AUTOSAR XML (schema 4-0-3)
package /ComponentTypes
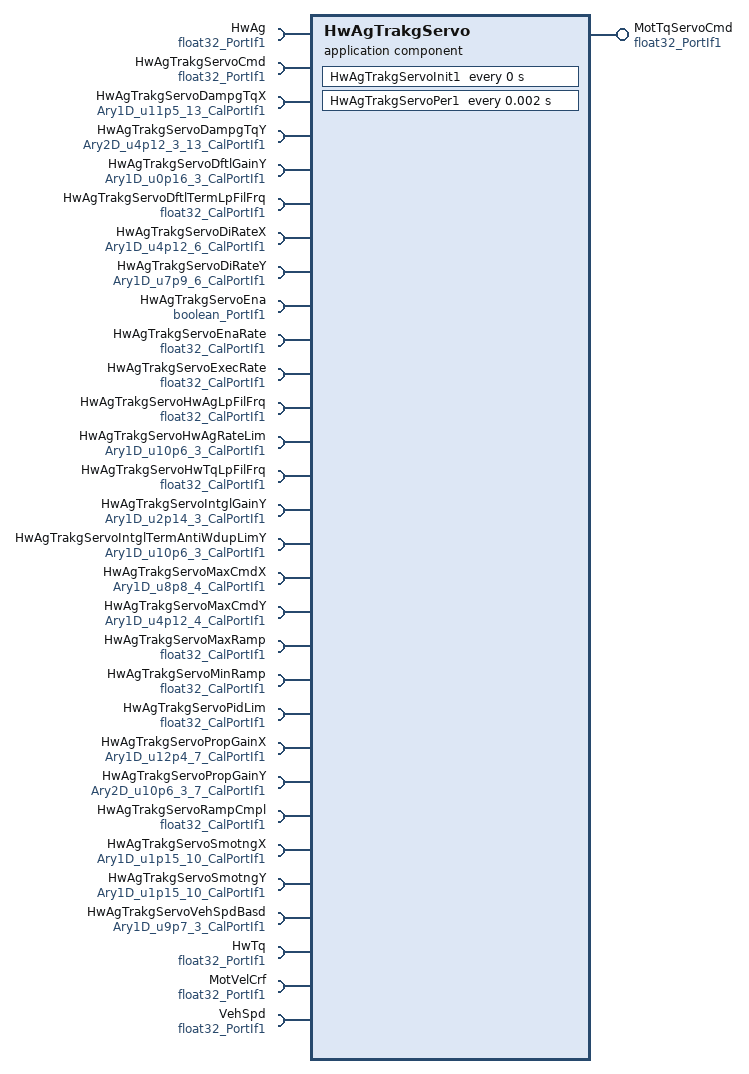
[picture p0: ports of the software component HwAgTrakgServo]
  application sw component type HwAgTrakgServo
    provide port MotTqServoCmd: nonqueued-sender-com-spec{data-element=Val, init-value=0.0}, provided-interface=float32_PortIf1
    30 x require port:
      HwAg: nonqueued-receiver-com-spec{data-element=Val, filter=data-filter-type=ALWAYS, init-value=0.0}, required-interface=float32_PortIf1
      HwAgTrakgServoCmd: nonqueued-receiver-com-spec{data-element=Val, filter=data-filter-type=ALWAYS, init-value=0.0}, required-interface=float32_PortIf1
      HwAgTrakgServoDampgTqX: parameter-require-com-spec{init-value=[0, 3200, 6400, 10724, 11260, 12064, 12868, 13940, 14744, 16620, 21448, 24128, 26808], parameter=Ary1D}, required-interface=Ary1D_u11p5_13_CalPortIf1
      HwAgTrakgServoDampgTqY: parameter-require-com-spec{init-value=[[0, 1434, 2867, 4804, 5097, 5593, 6175, 6961, 7595, 8982, 12135, 13677, 15082], [0, 1434, 2867, 4804, 5097, 5593, 6175, 6961, 7595, 8982, 12135, 13677, 15082], [0, 1434, 2867, 4804, 5097, 5593, 6175, 6961, 7595, 8982, 12135, 13677, 15082]], parameter=Ary2D}, required-interface=Ary2D_u4p12_3_13_CalPortIf1
      HwAgTrakgServoDftlGainY: parameter-require-com-spec{init-value=[393, 393, 393], parameter=Ary1D}, required-interface=Ary1D_u0p16_3_CalPortIf1
      HwAgTrakgServoDftlTermLpFilFrq: parameter-require-com-spec{init-value=10.0, parameter=Val}, required-interface=float32_CalPortIf1
      HwAgTrakgServoDiRateX: parameter-require-com-spec{init-value=[0, 4096, 8192, 12288, 16384, 28672], parameter=Ary1D}, required-interface=Ary1D_u4p12_6_CalPortIf1
      HwAgTrakgServoDiRateY: parameter-require-com-spec{init-value=[154, 205, 256, 512, 1024, 2560], parameter=Ary1D}, required-interface=Ary1D_u7p9_6_CalPortIf1
      HwAgTrakgServoEna: nonqueued-receiver-com-spec{data-element=Logl, filter=data-filter-type=ALWAYS, init-value=0}, required-interface=boolean_PortIf1
      HwAgTrakgServoEnaRate: parameter-require-com-spec{init-value=0.0, parameter=Val}, required-interface=float32_CalPortIf1
      HwAgTrakgServoExecRate: parameter-require-com-spec{init-value=500.0, parameter=Val}, required-interface=float32_CalPortIf1
      HwAgTrakgServoHwAgLpFilFrq: parameter-require-com-spec{init-value=2.0, parameter=Val}, required-interface=float32_CalPortIf1
      HwAgTrakgServoHwAgRateLim: parameter-require-com-spec{init-value=[38400, 38400, 38400], parameter=Ary1D}, required-interface=Ary1D_u10p6_3_CalPortIf1
      HwAgTrakgServoHwTqLpFilFrq: parameter-require-com-spec{init-value=2.0, parameter=Val}, required-interface=float32_CalPortIf1
      HwAgTrakgServoIntglGainY: parameter-require-com-spec{init-value=[4915, 4915, 4915], parameter=Ary1D}, required-interface=Ary1D_u2p14_3_CalPortIf1
      HwAgTrakgServoIntglTermAntiWdupLimY: parameter-require-com-spec{init-value=[128, 96, 64], parameter=Ary1D}, required-interface=Ary1D_u10p6_3_CalPortIf1
      HwAgTrakgServoMaxCmdX: parameter-require-com-spec{init-value=[0, 1280, 3072, 3098], parameter=Ary1D}, required-interface=Ary1D_u8p8_4_CalPortIf1
      HwAgTrakgServoMaxCmdY: parameter-require-com-spec{init-value=[36045, 36045, 36045, 36045], parameter=Ary1D}, required-interface=Ary1D_u4p12_4_CalPortIf1
      HwAgTrakgServoMaxRamp: parameter-require-com-spec{init-value=1.0, parameter=Val}, required-interface=float32_CalPortIf1
      HwAgTrakgServoMinRamp: parameter-require-com-spec{init-value=0.0, parameter=Val}, required-interface=float32_CalPortIf1
      HwAgTrakgServoPidLim: parameter-require-com-spec{init-value=3.2578125, parameter=Val}, required-interface=float32_CalPortIf1
      HwAgTrakgServoPropGainX: parameter-require-com-spec{init-value=[0, 128, 256, 512, 1280, 1600, 1920], parameter=Ary1D}, required-interface=Ary1D_u12p4_7_CalPortIf1
      HwAgTrakgServoPropGainY: parameter-require-com-spec{init-value=[[0, 6, 16, 47, 179, 205, 208], [0, 6, 16, 47, 179, 205, 208], [0, 6, 16, 47, 179, 205, 208]], parameter=Ary2D}, required-interface=Ary2D_u10p6_3_7_CalPortIf1
      HwAgTrakgServoRampCmpl: parameter-require-com-spec{init-value=0.0, parameter=Val}, required-interface=float32_CalPortIf1
      HwAgTrakgServoSmotngX: parameter-require-com-spec{init-value=[0, 3277, 6554, 9830, 13107, 19661, 22938, 26214, 29491, 32768], parameter=Ary1D}, required-interface=Ary1D_u1p15_10_CalPortIf1
      HwAgTrakgServoSmotngY: parameter-require-com-spec{init-value=[0, 786, 3113, 6750, 11305, 21463, 26018, 29655, 31982, 32768], parameter=Ary1D}, required-interface=Ary1D_u1p15_10_CalPortIf1
      HwAgTrakgServoVehSpdBasd: parameter-require-com-spec{init-value=[0, 512, 1280], parameter=Ary1D}, required-interface=Ary1D_u9p7_3_CalPortIf1
      HwTq: nonqueued-receiver-com-spec{data-element=Val, filter=data-filter-type=ALWAYS, init-value=0.0}, required-interface=float32_PortIf1
      MotVelCrf: nonqueued-receiver-com-spec{data-element=Val, filter=data-filter-type=ALWAYS, init-value=0.0}, required-interface=float32_PortIf1
      VehSpd: nonqueued-receiver-com-spec{data-element=Val, filter=data-filter-type=ALWAYS, init-value=0.0}, required-interface=float32_PortIf1
    behavior HwAgTrakgServo_InternalBehavior
      ar-typed-per-instance-memorys:
        16 x data, all with sw-calibration-access=READ-ONLY:
          DftlTermLpFil: type=FilLpRec1
          dHwAgTrakgServoDftlTerm: type=float32
          dHwAgTrakgServoHwAgTarFild: type=float32
          dHwAgTrakgServoIntglTerm: type=float32
          dHwAgTrakgServoPidCmd: type=float32
          dHwAgTrakgServoPropTerm: type=float32
          dHwAgTrakgServoRampCmpl: type=boolean
          dHwAgTrakgServoRtnScaFac: type=float32
          dHwAgTrakgServoSmotngEna: type=float32
          HwAgLpFil: type=FilLpRec1
          HwAgTarRateLim: type=float32
          HwTqLpFil: type=FilLpRec1
          PrevDftlErr: type=float32
          PrevHwAgTar: type=float32
          PrevIntglErr: type=float32
          PrevSmotng: type=float32
      timing event HwAgTrakgServo_InitEvent: start-on-event=HwAgTrakgServoInit1, period=0
      timing event TMT_HwAgTrakgServoPer1: start-on-event=HwAgTrakgServoPer1, period=0.002
      runnable HwAgTrakgServoInit1
      runnable HwAgTrakgServoPer1: minimum-start-interval=0.002
        data-receive-point-by-arguments:
          6 x access:
            REC_HwAg_Val: accessed-variable=HwAg.Val
            REC_HwAgTrakgServoCmd_Val: accessed-variable=HwAgTrakgServoCmd.Val
            REC_HwAgTrakgServoEna_Logl: accessed-variable=HwAgTrakgServoEna.Logl
            REC_HwTq_Val: accessed-variable=HwTq.Val
            REC_MotVelCrf_Val: accessed-variable=MotVelCrf.Val
            REC_VehSpd_Val: accessed-variable=VehSpd.Val
        data-send-points:
          access SEND_MotTqServoCmd_Val: accessed-variable=MotTqServoCmd.Val
  swc implementation HwAgTrakgServo_Implementation: behavior=HwAgTrakgServo_InternalBehavior
    code-descriptors:
      code Default: artifact-descriptors=autosar-engineering-object={short-label=Default, category=SWSRC}
